# STM32H7B0xx register map
File version: 1.0
Registers are 32-bit, access not given, reset 0x0 unless marked. A register's access mark holds for its fields unless they carry their own. Offsets are from the block's base; [hi:lo] are bit positions; {n}, {i} and the like mark numbered series.

## FDCAN_CCU
Base 0x4000A800
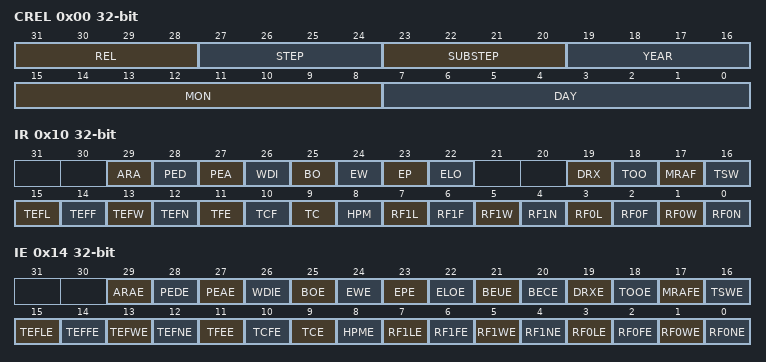
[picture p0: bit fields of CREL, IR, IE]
0x00 CREL
  [31:28] REL, [27:24] STEP, [23:20] SUBSTEP, [19:16] YEAR, [15:8] MON, [7:0] DAY
0x04 CCFG
0x08 CSTAT
0x0C CWD
0x10 IR
  [29] ARA, [28] PED, [27] PEA, [26] WDI, [25] BO, [24] EW, [23] EP, [22] ELO, [19] DRX, [18] TOO, [17] MRAF, [16] TSW, [15] TEFL, [14] TEFF, [13] TEFW, [12] TEFN, [11] TFE, [10] TCF, [9] TC, [8] HPM, [7] RF1L, [6] RF1F, [5] RF1W, [4] RF1N, [3] RF0L, [2] RF0F, [1] RF0W, [0] RF0N
0x14 IE
  [29] ARAE, [28] PEDE, [27] PEAE, [26] WDIE, [25] BOE, [24] EWE, [23] EPE, [22] ELOE, [21] BEUE, [20] BECE, [19] DRXE, [18] TOOE, [17] MRAFE, [16] TSWE, [15] TEFLE, [14] TEFFE, [13] TEFWE, [12] TEFNE, [11] TFEE, [10] TCFE, [9] TCE, [8] HPME, [7] RF1LE, [6] RF1FE, [5] RF1WE, [4] RF1NE, [3] RF0LE, [2] RF0FE, [1] RF0WE, [0] RF0NE

## SAI1
Base 0x40015800
Same registers: SAI2 0x40015C00
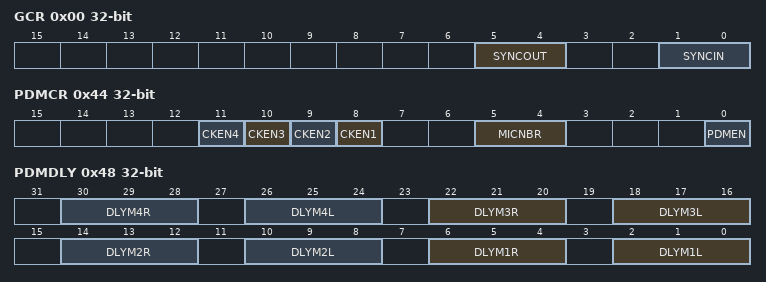
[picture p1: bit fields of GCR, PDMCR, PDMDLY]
0x00 GCR
  [5:4] SYNCOUT, [1:0] SYNCIN
0x04 CR1A
0x08 CR2A
0x10 FRCRA
0x1C SLOTRA
0x24 CR1B
0x28 CR2B
0x2C IMRA
0x30 FRCRB
0x3C SLOTRB
0x40 SRA
0x44 PDMCR
  [n+7] CKEN{n} (n=1..4), [5:4] MICNBR, [0] PDMEN
0x48 PDMDLY
  [8n-2:8n-4] DLYM{n}R (n=1..4), [8n-6:8n-8] DLYM{n}L (n=1..4)
0x4C IMRB
0x58 CLRFRA
0x60 SRB
0x74 DRA
0x78 CLRFRB
0x94 DRB

## DMA1
Base 0x40020000
Same registers: DMA2 0x40020400
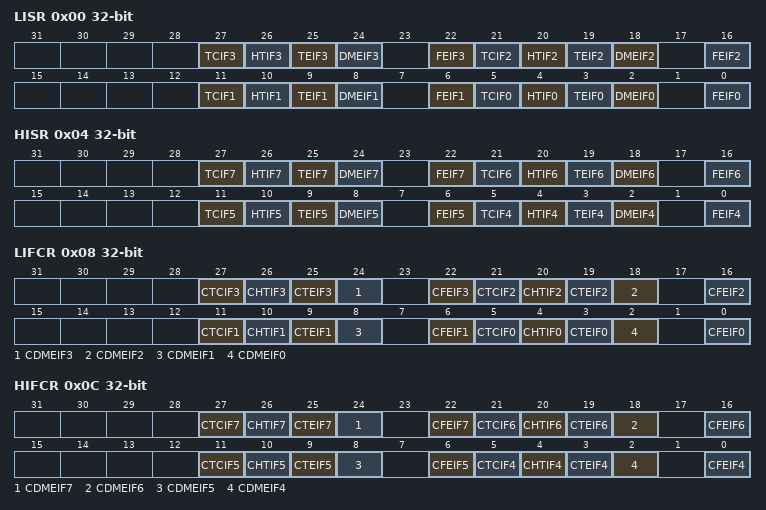
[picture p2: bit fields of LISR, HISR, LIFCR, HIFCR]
0x00 LISR
  [27] TCIF3, [26] HTIF3, [25] TEIF3, [24] DMEIF3, [22] FEIF3, [21] TCIF2, [20] HTIF2, [19] TEIF2, [18] DMEIF2, [16] FEIF2, [11] TCIF1, [10] HTIF1, [9] TEIF1, [8] DMEIF1, [6] FEIF1, [5] TCIF0, [4] HTIF0, [3] TEIF0, [2] DMEIF0, [0] FEIF0
0x04 HISR
  [27] TCIF7, [26] HTIF7, [25] TEIF7, [24] DMEIF7, [22] FEIF7, [21] TCIF6, [20] HTIF6, [19] TEIF6, [18] DMEIF6, [16] FEIF6, [11] TCIF5, [10] HTIF5, [9] TEIF5, [8] DMEIF5, [6] FEIF5, [5] TCIF4, [4] HTIF4, [3] TEIF4, [2] DMEIF4, [0] FEIF4
0x08 LIFCR
  [27] CTCIF3, [26] CHTIF3, [25] CTEIF3, [24] CDMEIF3, [22] CFEIF3, [21] CTCIF2, [20] CHTIF2, [19] CTEIF2, [18] CDMEIF2, [16] CFEIF2, [11] CTCIF1, [10] CHTIF1, [9] CTEIF1, [8] CDMEIF1, [6] CFEIF1, [5] CTCIF0, [4] CHTIF0, [3] CTEIF0, [2] CDMEIF0, [0] CFEIF0
0x0C HIFCR
  [27] CTCIF7, [26] CHTIF7, [25] CTEIF7, [24] CDMEIF7, [22] CFEIF7, [21] CTCIF6, [20] CHTIF6, [19] CTEIF6, [18] CDMEIF6, [16] CFEIF6, [11] CTCIF5, [10] CHTIF5, [9] CTEIF5, [8] CDMEIF5, [6] CFEIF5, [5] CTCIF4, [4] CHTIF4, [3] CTEIF4, [2] CDMEIF4, [0] CFEIF4
{0x10+0x18*i} CR{i} (i=0..7)
{0x14+0x18*i} NDTR{i} (i=0..7)
{0x1C+0x18*i} PAR{i} (i=0..7)
{0x28+0x18*i} M0AR{i} (i=0..7)
{0x38+0x18*i} M1AR{i} (i=0..7)
{0x4C+0x18*i} FCR{i} (i=0..7)

## DMAMUX1
Base 0x40020800
Same registers: DMAMUX2 0x58025800
0x00 CCR0
0x04 CCR1
0x08 CCR2
0x0C CCR3
0x10 CCR4
0x14 CCR5
0x18 CCR6
0x1C CCR7
0x20 CCR8
0x24 CCR9
0x28 CCR0
0x2C CCR1
0x30 CCR2
0x34 CCR3
0x38 CCR4
0x3C CCR5
0x80 CCRs
0x100 CCR0
0x104 CCR1
0x108 CCR2
0x10C CCR3
0x110 CCR4
0x114 CCR5
0x118 CCR6
0x11C CCR7
0x140 CCRs

## ADC1
Base 0x40022000
Same registers: ADC2 0x40022100
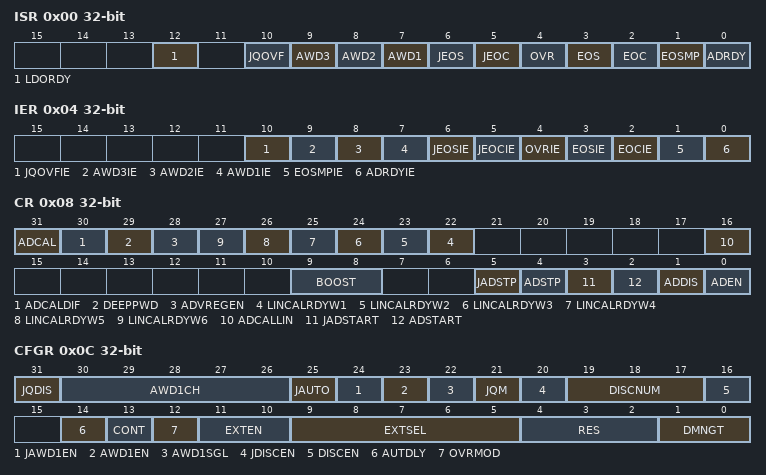
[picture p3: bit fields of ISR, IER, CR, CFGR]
0x00 ISR
  [12] LDORDY, [10] JQOVF, [9] AWD3, [8] AWD2, [7] AWD1, [6] JEOS, [5] JEOC, [4] OVR, [3] EOS, [2] EOC, [1] EOSMP, [0] ADRDY
0x04 IER
  [10] JQOVFIE, [9] AWD3IE, [8] AWD2IE, [7] AWD1IE, [6] JEOSIE, [5] JEOCIE, [4] OVRIE, [3] EOSIE, [2] EOCIE, [1] EOSMPIE, [0] ADRDYIE
0x08 CR
  [31] ADCAL, [30] ADCALDIF, [29] DEEPPWD, [28] ADVREGEN, [n+21] LINCALRDYW{n} (n=1..6), [16] ADCALLIN, [9:8] BOOST, [5] JADSTP, [4] ADSTP, [3] JADSTART, [2] ADSTART, [1] ADDIS, [0] ADEN
0x0C CFGR
  [31] JQDIS, [30:26] AWD1CH, [25] JAUTO, [24] JAWD1EN, [23] AWD1EN, [22] AWD1SGL, [21] JQM, [20] JDISCEN, [19:17] DISCNUM, [16] DISCEN, [14] AUTDLY, [13] CONT, [12] OVRMOD, [11:10] EXTEN, [9:5] EXTSEL, [4:2] RES, [1:0] DMNGT
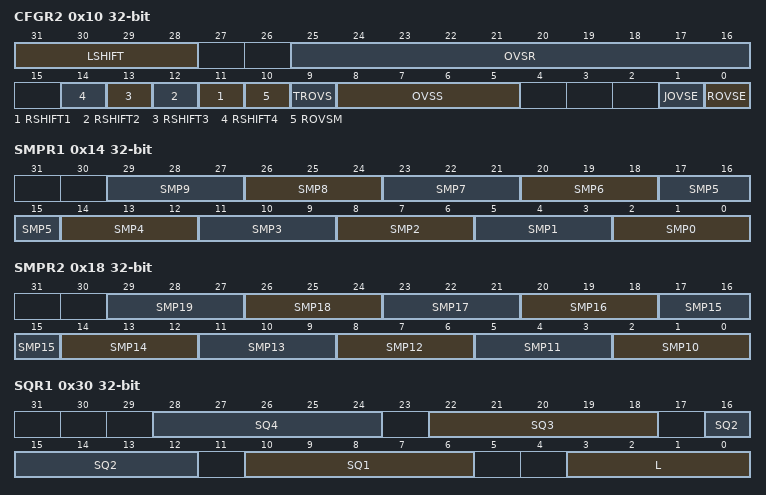
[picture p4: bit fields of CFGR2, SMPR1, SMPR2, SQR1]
0x10 CFGR2
  [31:28] LSHIFT, [25:16] OVSR, [n+10] RSHIFT{n} (n=1..4), [10] ROVSM, [9] TROVS, [8:5] OVSS, [1] JOVSE, [0] ROVSE
0x14 SMPR1
  [3n+2:3n] SMP{n} (n=0..9)
0x18 SMPR2
  [3n-28:3n-30] SMP{n} (n=10..19)
0x1C PCSEL
  [19:0] PCSEL
0x20 LTR1
0x24 HTR1
0x30 SQR1
  [6n+4:6n] SQ{n} (n=1..4), [3:0] L
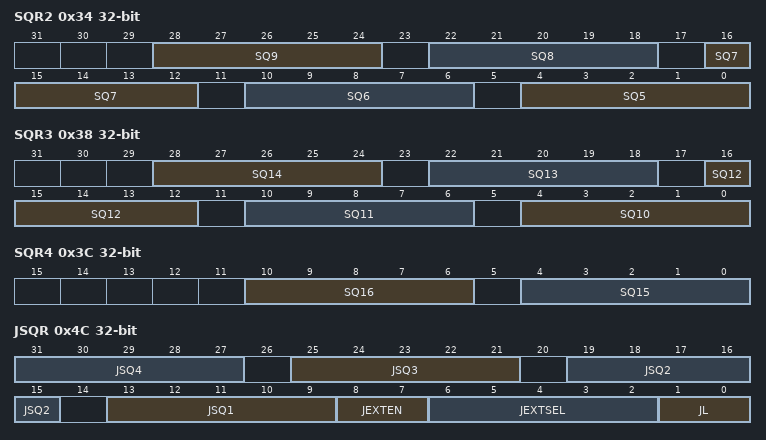
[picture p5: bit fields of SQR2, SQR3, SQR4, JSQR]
0x34 SQR2
  [6n-26:6n-30] SQ{n} (n=5..9)
0x38 SQR3
  [6n-56:6n-60] SQ{n} (n=10..14)
0x3C SQR4
  [10:6] SQ16, [4:0] SQ15
0x40 DR
  [31:0] RDATA
0x4C JSQR
  [6n+7:6n+3] JSQ{n} (n=1..4), [8:7] JEXTEN, [6:2] JEXTSEL, [1:0] JL
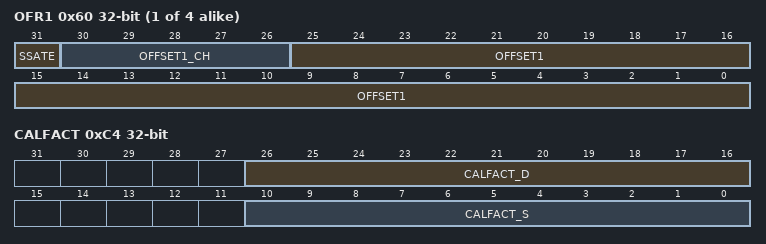
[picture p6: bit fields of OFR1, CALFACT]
{0x5C+4i} OFR{i} (i=1..4)
  [31] SSATE, [30:26] OFFSET{i}_CH, [25:0] OFFSET{i}
{0x7C+4i} JDR{i} (i=1..4)
  [31:0] JDATA
0xA0 AWD2CR
  [19:0] AWD2CH
0xA4 AWD3CR
  [19:0] AWD3CH
0xB0 LTR2
0xB4 HTR2
0xB8 LTR3
0xBC HTR3
0xC0 DIFSEL
  [19:0] DIFSEL
0xC4 CALFACT
  [26:16] CALFACT_D, [10:0] CALFACT_S
0xC8 CALFACT2
  [29:0] LINCALFACT
